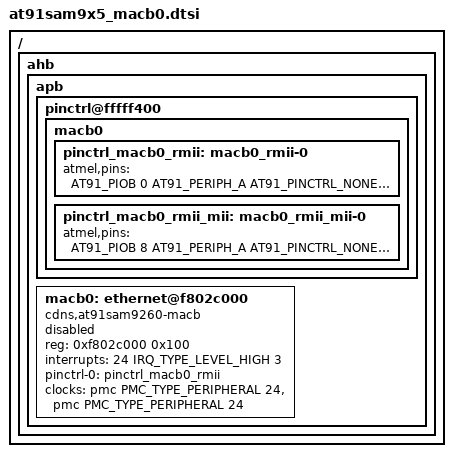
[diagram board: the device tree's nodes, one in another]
#include <dt-bindings/pinctrl/at91.h>
#include <dt-bindings/interrupt-controller/irq.h>
/ {
	ahb {
		apb {
			pinctrl@fffff400 {
				macb0 {
					pinctrl_macb0_rmii: macb0_rmii-0 {
						atmel,pins =
							<AT91_PIOB 0 AT91_PERIPH_A AT91_PINCTRL_NONE	 
							 AT91_PIOB 1 AT91_PERIPH_A AT91_PINCTRL_NONE	 
							 AT91_PIOB 2 AT91_PERIPH_A AT91_PINCTRL_NONE	 
							 AT91_PIOB 3 AT91_PERIPH_A AT91_PINCTRL_NONE	 
							 AT91_PIOB 4 AT91_PERIPH_A AT91_PINCTRL_NONE	 
							 AT91_PIOB 5 AT91_PERIPH_A AT91_PINCTRL_NONE	 
							 AT91_PIOB 6 AT91_PERIPH_A AT91_PINCTRL_NONE	 
							 AT91_PIOB 7 AT91_PERIPH_A AT91_PINCTRL_NONE	 
							 AT91_PIOB 9 AT91_PERIPH_A AT91_PINCTRL_NONE	 
							 AT91_PIOB 10 AT91_PERIPH_A AT91_PINCTRL_NONE>;	 
					};
					pinctrl_macb0_rmii_mii: macb0_rmii_mii-0 {
						atmel,pins =
							<AT91_PIOB 8 AT91_PERIPH_A AT91_PINCTRL_NONE	 
							 AT91_PIOB 11 AT91_PERIPH_A AT91_PINCTRL_NONE	 
							 AT91_PIOB 12 AT91_PERIPH_A AT91_PINCTRL_NONE	 
							 AT91_PIOB 13 AT91_PERIPH_A AT91_PINCTRL_NONE	 
							 AT91_PIOB 14 AT91_PERIPH_A AT91_PINCTRL_NONE	 
							 AT91_PIOB 15 AT91_PERIPH_A AT91_PINCTRL_NONE	 
							 AT91_PIOB 16 AT91_PERIPH_A AT91_PINCTRL_NONE	 
							 AT91_PIOB 17 AT91_PERIPH_A AT91_PINCTRL_NONE>;	 
					};
				};
			};
			macb0: ethernet@f802c000 {
				compatible = "cdns,at91sam9260-macb", "cdns,macb";
				reg = <0xf802c000 0x100>;
				interrupts = <24 IRQ_TYPE_LEVEL_HIGH 3>;
				pinctrl-names = "default";
				pinctrl-0 = <&pinctrl_macb0_rmii>;
				clocks = <&pmc PMC_TYPE_PERIPHERAL 24>, <&pmc PMC_TYPE_PERIPHERAL 24>;
				clock-names = "hclk", "pclk";
				status = "disabled";
			};
		};
	};
};
